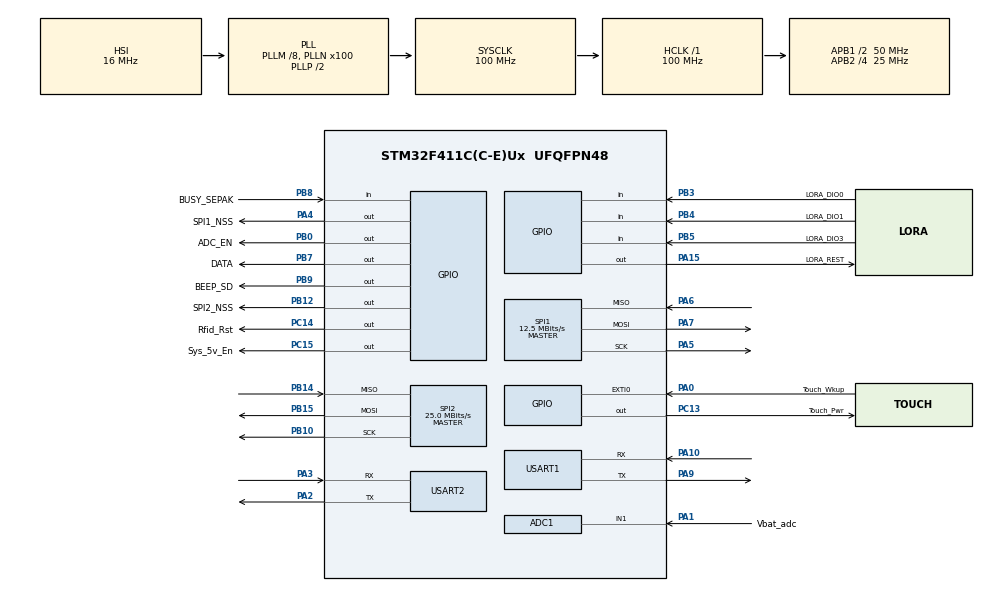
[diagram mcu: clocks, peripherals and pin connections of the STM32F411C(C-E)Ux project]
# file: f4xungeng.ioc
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ADC1.Channel-0\#ChannelRegularConversion=ADC_CHANNEL_1
ADC1.NbrOfConversionFlag=1
ADC1.Rank-0\#ChannelRegularConversion=1
ADC1.SamplingTime-0\#ChannelRegularConversion=ADC_SAMPLETIME_3CYCLES
ADC1.master=1
Dma.Request0=USART1_RX
Dma.Request1=USART2_RX
Dma.USART1_RX.0.Direction=DMA_PERIPH_TO_MEMORY
Dma.USART1_RX.0.FIFOMode=DMA_FIFOMODE_DISABLE
Dma.USART1_RX.0.Instance=DMA2_Stream2
Dma.USART1_RX.0.MemDataAlignment=DMA_MDATAALIGN_BYTE
Dma.USART1_RX.0.MemInc=DMA_MINC_ENABLE
Dma.USART1_RX.0.Mode=DMA_NORMAL
Dma.USART1_RX.0.PeriphDataAlignment=DMA_PDATAALIGN_BYTE
Dma.USART1_RX.0.PeriphInc=DMA_PINC_DISABLE
Dma.USART1_RX.0.Priority=DMA_PRIORITY_LOW
Dma.USART2_RX.1.Direction=DMA_PERIPH_TO_MEMORY
Dma.USART2_RX.1.FIFOMode=DMA_FIFOMODE_DISABLE
Dma.USART2_RX.1.Instance=DMA1_Stream5
Dma.USART2_RX.1.MemDataAlignment=DMA_MDATAALIGN_BYTE
Dma.USART2_RX.1.MemInc=DMA_MINC_ENABLE
Dma.USART2_RX.1.Mode=DMA_NORMAL
Dma.USART2_RX.1.PeriphDataAlignment=DMA_PDATAALIGN_BYTE
Dma.USART2_RX.1.PeriphInc=DMA_PINC_DISABLE
Dma.USART2_RX.1.Priority=DMA_PRIORITY_LOW
Mcu.Family=STM32F4
Mcu.Name=STM32F411C(C-E)Ux
Mcu.Package=UFQFPN48
NVIC.DMA1_Stream5_IRQn=true\:0\:0\:false\:true\:true\:3\:false\:true
NVIC.DMA2_Stream2_IRQn=true\:0\:0\:false\:true\:true\:5\:false\:true
NVIC.EXTI0_IRQn=true\:0\:0\:false\:true\:true\:1\:true\:true
NVIC.PriorityGroup=NVIC_PRIORITYGROUP_4
NVIC.TIM3_IRQn=true\:0\:0\:false\:false\:true\:false\:true
NVIC.TimeBase=TIM3_IRQn
NVIC.TimeBaseIP=TIM3
NVIC.USART1_IRQn=true\:0\:0\:false\:true\:true\:2\:true\:true
NVIC.USART2_IRQn=true\:0\:0\:false\:true\:true\:4\:true\:true
PA0-WKUP.GPIO_Label=Touch_Wkup
PA0-WKUP.GPIO_PuPd=GPIO_PULLUP
PA0-WKUP.Signal=GPXTI0
PA1.GPIO_Label=Vbat_adc
PA1.Signal=ADCx_IN1
PA10.Mode=Asynchronous
PA10.Signal=USART1_RX
PA13.Mode=Serial_Wire
PA13.Signal=SYS_JTMS-SWDIO
PA14.Mode=Serial_Wire
PA14.Signal=SYS_JTCK-SWCLK
PA15.GPIO_Label=LORA_REST
PA15.Signal=GPIO_Output
PA2.Mode=Asynchronous
PA2.Signal=USART2_TX
PA3.Mode=Asynchronous
PA3.Signal=USART2_RX
PA4.GPIO_Label=SPI1_NSS
PA4.Signal=GPIO_Output
PA5.Mode=Full_Duplex_Master
PA5.Signal=SPI1_SCK
PA6.Mode=Full_Duplex_Master
PA6.Signal=SPI1_MISO
PA7.Mode=Full_Duplex_Master
PA7.Signal=SPI1_MOSI
PA9.Mode=Asynchronous
PA9.Signal=USART1_TX
PB0.GPIO_Label=ADC_EN
PB0.Signal=GPIO_Output
PB10.Mode=Full_Duplex_Master
PB10.Signal=SPI2_SCK
PB12.GPIO_Label=SPI2_NSS
PB12.Signal=GPIO_Output
PB14.Mode=Full_Duplex_Master
PB14.Signal=SPI2_MISO
PB15.Mode=Full_Duplex_Master
PB15.Signal=SPI2_MOSI
PB3.GPIO_Label=LORA_DIO0
PB3.Signal=GPIO_Input
PB4.GPIO_Label=LORA_DIO1
PB4.Signal=GPIO_Input
PB5.GPIO_Label=LORA_DIO3
PB5.Signal=GPIO_Input
PB7.GPIO_Label=DATA
PB7.PinState=GPIO_PIN_SET
PB7.Signal=GPIO_Output
PB8.GPIO_Label=BUSY_SEPAK
PB8.Signal=GPIO_Input
PB9.GPIO_Label=BEEP_SD
PB9.PinState=GPIO_PIN_SET
PB9.Signal=GPIO_Output
PC13-ANTI_TAMP.GPIO_Label=Touch_Pwr
PC13-ANTI_TAMP.Signal=GPIO_Output
PC14-OSC32_IN.GPIO_Label=Rfid_Rst
PC14-OSC32_IN.Signal=GPIO_Output
PC15-OSC32_OUT.GPIO_Label=Sys_5v_En
PC15-OSC32_OUT.Signal=GPIO_Output
ProjectManager.HeapSize=0x400
ProjectManager.StackSize=0x400
ProjectManager.TargetToolchain=MDK-ARM V5.27
RCC.48MHZClocksFreq_Value=13333333.333333334
RCC.AHBFreq_Value=100000000
RCC.APB1CLKDivider=RCC_HCLK_DIV2
RCC.APB1Freq_Value=50000000
RCC.APB1TimFreq_Value=100000000
RCC.APB2CLKDivider=RCC_HCLK_DIV4
RCC.APB2Freq_Value=25000000
RCC.APB2TimFreq_Value=50000000
RCC.CortexFreq_Value=100000000
RCC.HCLKFreq_Value=100000000
RCC.HSE_VALUE=25000000
RCC.HSI_VALUE=16000000
RCC.LSE_VALUE=32768
RCC.PLLM=8
RCC.PLLN=100
RCC.PLLQ=15
RCC.SYSCLKFreq_VALUE=100000000
RCC.SYSCLKSource=RCC_SYSCLKSOURCE_PLLCLK
RCC.VCOOutputFreq_Value=200000000
SH.ADCx_IN1.0=ADC1_IN1,IN1
SPI1.BaudRatePrescaler=SPI_BAUDRATEPRESCALER_2
SPI1.CalculateBaudRate=12.5 MBits/s
SPI1.Direction=SPI_DIRECTION_2LINES
SPI1.Mode=SPI_MODE_MASTER
SPI1.VirtualType=VM_MASTER
SPI2.BaudRatePrescaler=SPI_BAUDRATEPRESCALER_2
SPI2.CalculateBaudRate=25.0 MBits/s
SPI2.Direction=SPI_DIRECTION_2LINES
SPI2.Mode=SPI_MODE_MASTER
SPI2.VirtualType=VM_MASTER
USART1.VirtualMode=VM_ASYNC
USART2.VirtualMode=VM_ASYNC
VP_SYS_VS_tim3.Mode=TIM3
board=custom

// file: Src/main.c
/* USER CODE BEGIN Header */
/**
  ******************************************************************************
  * @file           : main.c
  * @brief          : Main program body
  ******************************************************************************
  * @attention
  *
  * <h2><center>&copy; Copyright (c) 2021 STMicroelectronics.
  * All rights reserved.</center></h2>
  *
  * This software component is licensed by ST under BSD 3-Clause license,
  * the "License"; You may not use this file except in compliance with the
  * License. You may obtain a copy of the License at:
  *                        opensource.org/licenses/BSD-3-Clause
  *
  ******************************************************************************
  */
/* USER CODE END Header */

#include "main.h"
#include "adc.h"
#include "dma.h"
#include "spi.h"
#include "usart.h"
#include "gpio.h"

void SystemClock_Config(void);
static void MX_NVIC_Init(void);

int main(void)
{

  /* MCU Configuration--------------------------------------------------------*/

  /* Reset of all peripherals, Initializes the Flash interface and the Systick. */
  HAL_Init();

  /* Configure the system clock */
  SystemClock_Config();

  /* Initialize all configured peripherals */
  MX_GPIO_Init();
  MX_DMA_Init();
  MX_ADC1_Init();
  MX_SPI1_Init();
  MX_SPI2_Init();
  MX_USART1_UART_Init();
  MX_USART2_UART_Init();

  /* Initialize interrupts */
  MX_NVIC_Init();
  /* USER CODE BEGIN 2 */
//		app_lora_config_init();
	printf("AS608ָ��ʶ��ģ����Գ���");
  device();
  /* USER CODE END 2 */

  /* Infinite loop */
  /* USER CODE BEGIN WHILE */
  while (1)
  {
//		printf("play music");
//		Line_1A_WT588S(1);
//		HAL_Delay(5000);
		 app_task_run();
    /* USER CODE END WHILE */
//zhiwen_data_to_computer();
    /* USER CODE BEGIN 3 */
//		 zhiwen_data_to_computer();
  }
  /* USER CODE END 3 */
}

void SystemClock_Config(void)
{
  RCC_OscInitTypeDef RCC_OscInitStruct = {0};
  RCC_ClkInitTypeDef RCC_ClkInitStruct = {0};

  /** Configure the main internal regulator output voltage
  */
  __HAL_RCC_PWR_CLK_ENABLE();
  __HAL_PWR_VOLTAGESCALING_CONFIG(PWR_REGULATOR_VOLTAGE_SCALE1);
  /** Initializes the CPU, AHB and APB busses clocks
  */
  RCC_OscInitStruct.OscillatorType = RCC_OSCILLATORTYPE_HSI;
  RCC_OscInitStruct.HSIState = RCC_HSI_ON;
  RCC_OscInitStruct.HSICalibrationValue = RCC_HSICALIBRATION_DEFAULT;
  RCC_OscInitStruct.PLL.PLLState = RCC_PLL_ON;
  RCC_OscInitStruct.PLL.PLLSource = RCC_PLLSOURCE_HSI;
  RCC_OscInitStruct.PLL.PLLM = 8;
  RCC_OscInitStruct.PLL.PLLN = 100;
  RCC_OscInitStruct.PLL.PLLP = RCC_PLLP_DIV2;
  RCC_OscInitStruct.PLL.PLLQ = 15;
  if (HAL_RCC_OscConfig(&RCC_OscInitStruct) != HAL_OK)
  {
    Error_Handler();
  }
  /** Initializes the CPU, AHB and APB busses clocks
  */
  RCC_ClkInitStruct.ClockType = RCC_CLOCKTYPE_HCLK|RCC_CLOCKTYPE_SYSCLK
                              |RCC_CLOCKTYPE_PCLK1|RCC_CLOCKTYPE_PCLK2;
  RCC_ClkInitStruct.SYSCLKSource = RCC_SYSCLKSOURCE_PLLCLK;
  RCC_ClkInitStruct.AHBCLKDivider = RCC_SYSCLK_DIV1;
  RCC_ClkInitStruct.APB1CLKDivider = RCC_HCLK_DIV2;
  RCC_ClkInitStruct.APB2CLKDivider = RCC_HCLK_DIV4;

  if (HAL_RCC_ClockConfig(&RCC_ClkInitStruct, FLASH_LATENCY_3) != HAL_OK)
  {
    Error_Handler();
  }
}

/**
  * @brief NVIC Configuration.
  * @retval None
  */
static void MX_NVIC_Init(void)
{
  /* EXTI0_IRQn interrupt configuration */
  HAL_NVIC_SetPriority(EXTI0_IRQn, 0, 0);
  HAL_NVIC_EnableIRQ(EXTI0_IRQn);
  /* USART1_IRQn interrupt configuration */
  HAL_NVIC_SetPriority(USART1_IRQn, 0, 0);
  HAL_NVIC_EnableIRQ(USART1_IRQn);
  /* DMA1_Stream5_IRQn interrupt configuration */
  HAL_NVIC_SetPriority(DMA1_Stream5_IRQn, 0, 0);
  HAL_NVIC_EnableIRQ(DMA1_Stream5_IRQn);
  /* USART2_IRQn interrupt configuration */
  HAL_NVIC_SetPriority(USART2_IRQn, 0, 0);
  HAL_NVIC_EnableIRQ(USART2_IRQn);
  /* DMA2_Stream2_IRQn interrupt configuration */
  HAL_NVIC_SetPriority(DMA2_Stream2_IRQn, 0, 0);
  HAL_NVIC_EnableIRQ(DMA2_Stream2_IRQn);
}

 /**
  * @brief  Period elapsed callback in non blocking mode
  * @note   This function is called  when TIM3 interrupt took place, inside
  * HAL_TIM_IRQHandler(). It makes a direct call to HAL_IncTick() to increment
  * a global variable "uwTick" used as application time base.
  * @param  htim : TIM handle
  * @retval None
  */
void HAL_TIM_PeriodElapsedCallback(TIM_HandleTypeDef *htim)
{
  if (htim->Instance == TIM3) {
    HAL_IncTick();
  }
}

void Error_Handler(void)
{
}

/************************ (C) COPYRIGHT STMicroelectronics *****END OF FILE****/
